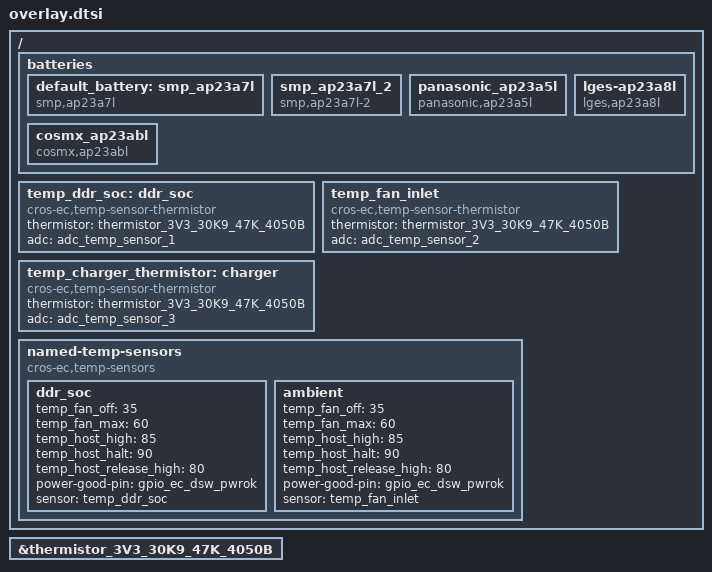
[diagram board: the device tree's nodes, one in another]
/* Copyright 2024 The ChromiumOS Authors
 * Use of this source code is governed by a BSD-style license that can be
 * found in the LICENSE file.
 */
#include <cros/thermistor/thermistor.dtsi>

/ {
	batteries {
		default_battery: smp_ap23a7l {
			compatible = "smp,ap23a7l", "battery-smart";
		};
		smp_ap23a7l_2 {
			compatible = "smp,ap23a7l-2", "battery-smart";
		};
		panasonic_ap23a5l {
			compatible = "panasonic,ap23a5l", "battery-smart";
		};
		lges-ap23a8l {
			compatible = "lges,ap23a8l", "battery-smart";
		};
		cosmx_ap23abl {
			compatible = "cosmx,ap23abl", "battery-smart";
		};
	};

	temp_ddr_soc: ddr_soc {
		 compatible = "cros-ec,temp-sensor-thermistor";
		 thermistor = <&thermistor_3V3_30K9_47K_4050B>;
		 adc = <&adc_temp_sensor_1>;
	 };
	 temp_fan_inlet: temp_fan_inlet {
		compatible = "cros-ec,temp-sensor-thermistor";
		thermistor = <&thermistor_3V3_30K9_47K_4050B>;
		adc = <&adc_temp_sensor_2>;
	};
	temp_charger_thermistor: charger {
		compatible = "cros-ec,temp-sensor-thermistor";
		thermistor = <&thermistor_3V3_30K9_47K_4050B>;
		adc = <&adc_temp_sensor_3>;
	};

	named-temp-sensors {
		compatible = "cros-ec,temp-sensors";
		ddr_soc {
			temp_fan_off = <35>;
			temp_fan_max = <60>;
			temp_host_high = <85>;
			temp_host_halt = <90>;
			temp_host_release_high = <80>;
			power-good-pin = <&gpio_ec_dsw_pwrok>;
			sensor = <&temp_ddr_soc>;
		};

		ambient {
			temp_fan_off = <35>;
			temp_fan_max = <60>;
			temp_host_high = <85>;
			temp_host_halt = <90>;
			temp_host_release_high = <80>;
			power-good-pin = <&gpio_ec_dsw_pwrok>;
			sensor = <&temp_fan_inlet>;
		};
	};
};

&thermistor_3V3_30K9_47K_4050B {
	status = "okay";
};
